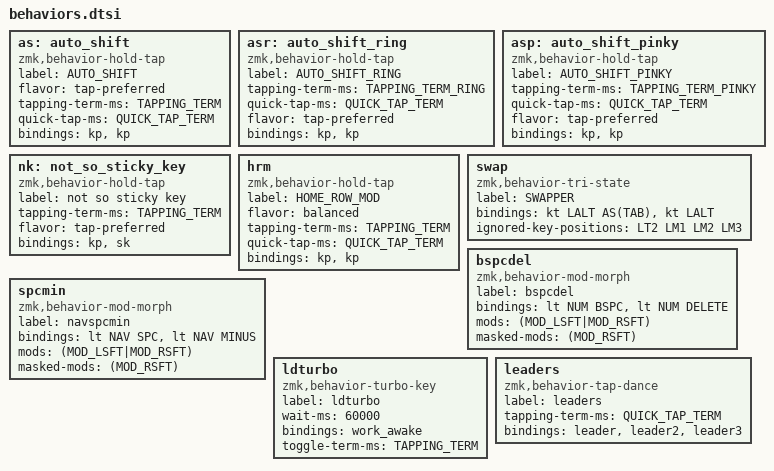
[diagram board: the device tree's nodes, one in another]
#define SK(KEY) &nk KEY KEY

#define RMODS (MOD_RGUI|MOD_RSFT|MOD_RALT|MOD_RCTL)
#define LMODS (MOD_LGUI|MOD_LSFT|MOD_LALT|MOD_LCTL)
#define ALLMODS (MOD_LGUI|MOD_LSFT|MOD_LALT|MOD_LCTL|MOD_RGUI|MOD_RSFT|MOD_RALT|MOD_RCTL)

as: auto_shift {
    compatible = "zmk,behavior-hold-tap";
    label = "AUTO_SHIFT";
    #binding-cells = <2>;
    flavor = "tap-preferred";
    tapping-term-ms = <TAPPING_TERM>;
    quick-tap-ms = <QUICK_TAP_TERM>;
    bindings = <&kp &kp>;
};

asr: auto_shift_ring {
    compatible = "zmk,behavior-hold-tap";
    label = "AUTO_SHIFT_RING";
    #binding-cells = <2>;
    tapping-term-ms = <TAPPING_TERM_RING>;
    quick-tap-ms = <QUICK_TAP_TERM>;
    flavor = "tap-preferred";
    bindings = <&kp &kp>;
};

asp: auto_shift_pinky {
    compatible = "zmk,behavior-hold-tap";
    label = "AUTO_SHIFT_PINKY";
    #binding-cells = <2>;
    tapping-term-ms = <TAPPING_TERM_PINKY>;
    quick-tap-ms = <QUICK_TAP_TERM>;
    flavor = "tap-preferred";
    bindings = <&kp &kp>;
};

nk: not_so_sticky_key {
    compatible = "zmk,behavior-hold-tap";
    label = "not so sticky key";
    #binding-cells = <2>;
    tapping-term-ms = <TAPPING_TERM>;
    flavor = "tap-preferred";
    bindings = <&kp &sk>;
};

hrm: hrm {
    compatible = "zmk,behavior-hold-tap";
    label = "HOME_ROW_MOD";
    #binding-cells = <2>;
    flavor = "balanced";
    tapping-term-ms = <TAPPING_TERM>;
    quick-tap-ms = <QUICK_TAP_TERM>;
    bindings = <&kp &kp>;
};

swap: swap {
    compatible = "zmk,behavior-tri-state";
    label = "SWAPPER";
    #binding-cells = <0>;
    bindings = <&kt LALT AS(TAB) &kt LALT>;
    ignored-key-positions = <LT2 LM1 LM2 LM3>;
};

bspcdel: bspcdel {
    compatible = "zmk,behavior-mod-morph";
    label = "bspcdel";
    #binding-cells = <0>;
    bindings = <&lt NUM BSPC &lt NUM DELETE>;
    mods = <(MOD_LSFT|MOD_RSFT)>;
    masked-mods = <(MOD_RSFT)>;
};

spcmin: spcmin {
    compatible = "zmk,behavior-mod-morph";
    label = "navspcmin";
    #binding-cells = <0>;
    bindings = <&lt NAV SPC &lt NAV MINUS>;
    mods = <(MOD_LSFT|MOD_RSFT)>;
    masked-mods = <(MOD_RSFT)>;
};

ldturbo: ldturbo {
    compatible = "zmk,behavior-turbo-key";
    label = "ldturbo";
    #binding-cells = <0>;
    wait-ms = <60000>;
    bindings = <&work_awake>;
    toggle-term-ms = <TAPPING_TERM>;
};

leaders: leaders {
    compatible = "zmk,behavior-tap-dance";
    label = "leaders";
    #binding-cells = <0>;
    tapping-term-ms = <QUICK_TAP_TERM>;
    bindings = <&leader &leader2 &leader3>;
};
